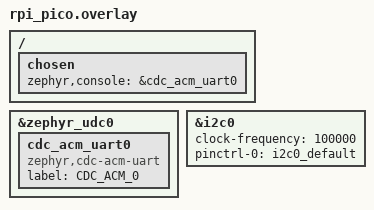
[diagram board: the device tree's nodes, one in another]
/ {
    
	chosen {
        zephyr,console = &cdc_acm_uart0;
    };
};

&zephyr_udc0 {
    cdc_acm_uart0: cdc_acm_uart0 {
        compatible = "zephyr,cdc-acm-uart";
        label = "CDC_ACM_0";
    };
};

&i2c0 {
    status = "okay";
    clock-frequency = <100000>;
    pinctrl-0 = <&i2c0_default>;
    pinctrl-names = "default";
};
